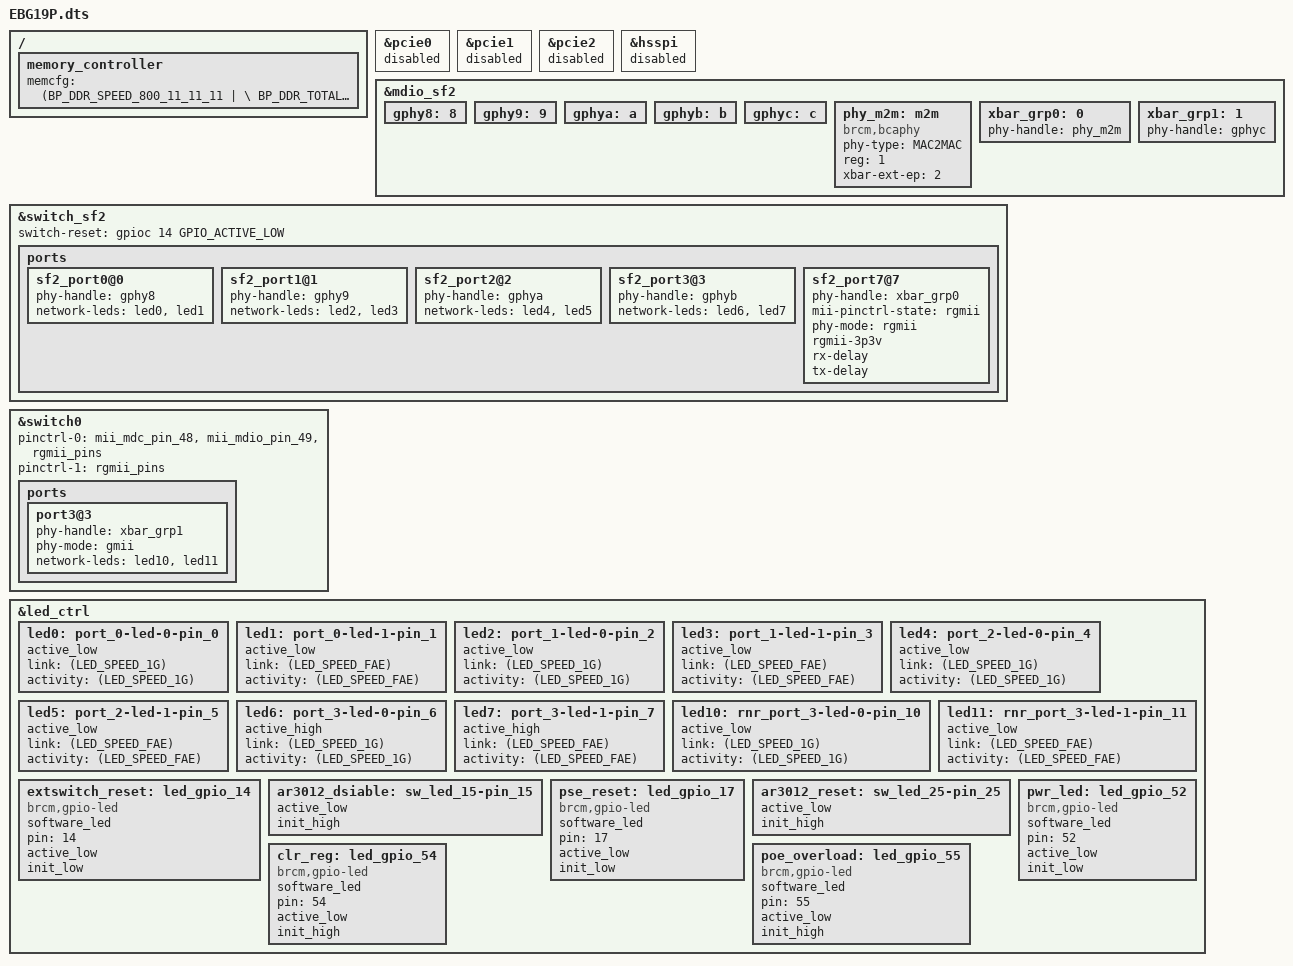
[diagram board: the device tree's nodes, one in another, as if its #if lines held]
#include "4908.dtsi"

/ {
    memory_controller {
        memcfg = <(BP_DDR_SPEED_800_11_11_11 | \
                   BP_DDR_TOTAL_SIZE_512MB   | \
                   BP_DDR_DEVICE_WIDTH_16    | \
                   BP_DDR_TOTAL_WIDTH_16BIT  | \
                   BP_DDR_SSC_CONFIG_1)>;
    };

/*
	buttons {
		compatible = "brcm,buttons";
		reset_button {
			ext_irq = <&bca_extintr 23 BCA_GPIO_ACTIVE_LOW (BCA_EXTINTR_TYPE_LOW_LEVEL | BCA_EXTINTR_TYPE_SENSE_LEVEL)>;
			press {
				print = "Button Press -- Hold for 5s to do restore to default";
			};
			hold {
				rst_to_dflt = <5>;
			};
			release {
				reset = <0>;
			};	
		};
		ses_button {
			ext_irq = <&bca_extintr 22 BCA_GPIO_ACTIVE_LOW (BCA_EXTINTR_TYPE_LOW_LEVEL | BCA_EXTINTR_TYPE_SENSE_LEVEL)>;
			release {
				ses_short_period = <0>;
				ses_long_period = <3>;
			};
		};
	};
*/
};

#if defined(CONFIG_BCM_PCIE_HCD) || defined(CONFIG_BCM_PCIE_HCD_MODULE)
&pcie0 {
    status = "disabled";
};
&pcie1 {
    status = "disabled";
};
&pcie2 {
    status = "disabled";
};
#endif //#if defined(CONFIG_BCM_PCIE_HCD) || defined(CONFIG_BCM_PCIE_HCD_MODULE)

&hsspi {
    status = "disabled";
};

&mdio_sf2 {
	/* PHYs directly connected to SF2 */
	gphy8:8 {
		status = "okay";
	};
	gphy9:9 {
		status = "okay";
	};
	gphya:a {
		status = "okay";
	};
	gphyb:b {
		status = "okay";
	};

	/* PHYs connected to crossbar */
	gphyc:c {
		status = "okay";
	};

	phy_m2m:m2m {
		compatible = "brcm,bcaphy";
		phy-type = "MAC2MAC";
		reg = <1>;
		xbar-ext-ep = <2>;          /* external endpoint2 */
		status = "okay";
	};

	/* Crossbar groups */
	xbar_grp0:0 {
		phy-handle = <&phy_m2m>;
		status = "okay";
	};

	xbar_grp1:1 {
		phy-handle = <&gphyc>;
		status = "okay";
	};
};

&switch_sf2 {
    switch-reset = <&gpioc 14 GPIO_ACTIVE_LOW>;

	ports {
		sf2_port0@0 {
			phy-handle = <&gphy8>;
            network-leds = <&led0 &led1>;
			status = "okay";
		};

		sf2_port1@1 {
			phy-handle = <&gphy9>;
            network-leds = <&led2 &led3>;
			status = "okay";
		};

		sf2_port2@2 {
			phy-handle = <&gphya>;
            network-leds = <&led4 &led5>;
			status = "okay";
		};

		sf2_port3@3 {
			phy-handle = <&gphyb>;
            network-leds = <&led6 &led7>;
			status = "okay";
		};

		sf2_port7@7 {
			phy-handle = <&xbar_grp0>;
			mii-pinctrl-state = "rgmii";
			phy-mode = "rgmii";
			rgmii-3p3v;
			rx-delay;
			tx-delay;
            status = "okay";
		};
	};
};

&switch0 {
	pinctrl-names = "default", "rgmii"; 
	pinctrl-0 = <&mii_mdc_pin_48 &mii_mdio_pin_49 &rgmii_pins>; 
	pinctrl-1 = <&rgmii_pins>; 

	ports {
		port3@3 {
			phy-handle = <&xbar_grp1>;
			phy-mode = "gmii";
            network-leds = <&led10 &led11>;
			status = "okay";
		};
	};
};

&led_ctrl {

    /* GPHY0 ~ GPHY3 SPD + ACT */
    /* GPHY0 */

    led0: port_0-led-0-pin_0 {
        active_low;
        link = <(LED_SPEED_1G)>;
        activity = <(LED_SPEED_1G)>;
        status = "okay";
    };

    led1: port_0-led-1-pin_1 {
        active_low;
        link = <(LED_SPEED_FAE)>;
        activity = <(LED_SPEED_FAE)>;
        status = "okay";
    };

    /* GPHY1 */

    led2: port_1-led-0-pin_2 {
        active_low;
        link = <(LED_SPEED_1G)>;
        activity = <(LED_SPEED_1G)>;
        status = "okay";
    };

    led3: port_1-led-1-pin_3 {
        active_low;
        link = <(LED_SPEED_FAE)>;
        activity = <(LED_SPEED_FAE)>;
        status = "okay";
    };

    /* GPHY2 */

    led4: port_2-led-0-pin_4 {
        active_low;
        link = <(LED_SPEED_1G)>;
        activity = <(LED_SPEED_1G)>;
        status = "okay";
    };

    led5: port_2-led-1-pin_5 {
        active_low;
        link = <(LED_SPEED_FAE)>;
        activity = <(LED_SPEED_FAE)>;
        status = "okay";
    };


    /* GPHY3 */

    led6: port_3-led-0-pin_6 {
        active_high;
        link = <(LED_SPEED_1G)>;
        activity = <(LED_SPEED_1G)>;
        status = "okay";
    };

    led7: port_3-led-1-pin_7 {
        active_high;
        link = <(LED_SPEED_FAE)>;
        activity = <(LED_SPEED_FAE)>;
        status = "okay";
    };


    /* WAN SPD + ACT */
    led10: rnr_port_3-led-0-pin_10 {
        active_low;
        link = <(LED_SPEED_1G)>;
        activity = <(LED_SPEED_1G)>;
        status = "okay";
    };

    led11: rnr_port_3-led-1-pin_11 {
        active_low;
        link = <(LED_SPEED_FAE)>;
        activity = <(LED_SPEED_FAE)>;
        status = "okay";
    };

    /* extswitch reset */
    extswitch_reset:led_gpio_14 {
        compatible = "brcm,gpio-led";
        software_led;
        pin = <14>;
        active_low;
        init_low;
        status = "okay";
    };

    /* ar3012_dsiable */
    ar3012_dsiable: sw_led_15-pin_15 {
        active_low;
        init_high;
        status = "okay";
    };

    /* pse reset */
    pse_reset:led_gpio_17 {
        compatible = "brcm,gpio-led";
        software_led;
        pin = <17>;
        active_low;
        init_low;
        status = "okay";
    };

    /* pse interrupt pin-18 */
    /* rtl8367s interrupt pin-20 */


    /* ar3012_reset */
    ar3012_reset: sw_led_25-pin_25 {
        active_low;
        init_high;
        status = "okay";
    };

    /* PWR LED */
    pwr_led:led_gpio_52 {
        compatible = "brcm,gpio-led";
        software_led;
        pin = <52>;
        active_low;
        init_low;
        status = "okay";
    };

    /* CLR_REG */
    clr_reg:led_gpio_54 {
        compatible = "brcm,gpio-led";
        software_led;
        pin = <54>;
        active_low;
        init_high;
        status = "okay";
    };

    /* poe_overload */
    poe_overload:led_gpio_55 {
        compatible = "brcm,gpio-led";
        software_led;
        pin = <55>;
        active_low;
        init_high;
        status = "okay";
    };

};
